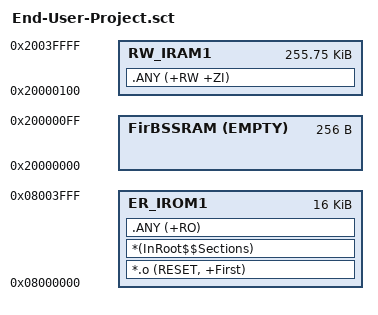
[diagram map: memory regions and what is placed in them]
; *************************************************************
; *** Scatter-Loading Description File generated by uVision ***
; *************************************************************

LR_IROM1 0x08000000 0x00004000  {    ; load region size_region
  ER_IROM1 0x08000000 0x00004000  {  ; load address = execution address
   *.o (RESET, +First)
   *(InRoot$$Sections)
   .ANY (+RO)
  }
    FirBSSRAM  0x20000000 EMPTY 0x100 ; RW and Zero Initialized data for fir filter  
  { 
  }  
  RW_IRAM1 0x20000100 0x0003FF00  {  ; RW data
   .ANY (+RW +ZI)
  }
}
